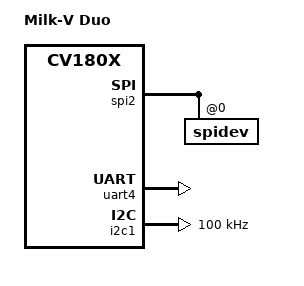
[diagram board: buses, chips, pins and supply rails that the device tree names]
/dts-v1/;
#include "cv180x_base_riscv.dtsi"
#include "cv180x_asic_qfn.dtsi"
#include "cv180x_asic_sd.dtsi"
#include "cv180x_default_memmap.dtsi"

&mipi_rx{
	snsr-reset = <&portc 8 GPIO_ACTIVE_LOW>, <&portc 8 GPIO_ACTIVE_LOW>, <&portc 8 GPIO_ACTIVE_LOW>;
};

&spi2 {
	status = "okay";

	spidev@0 {
		status = "okay";
	};
};

&uart4 {
	status = "okay";
};

&i2c1 {
       status = "okay";
       clock-frequency = <100000>;
};

/ {
	model = "Milk-V Duo";
};

